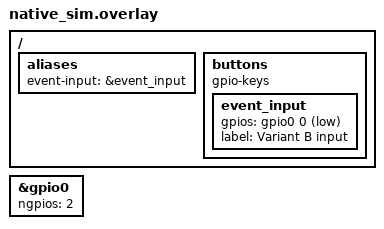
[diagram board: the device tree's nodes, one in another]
/ {
	aliases {
		event-input = &event_input;
	};

	buttons {
		compatible = "gpio-keys";

		event_input: event_input {
			gpios = <&gpio0 0 GPIO_ACTIVE_LOW>;
			label = "Variant B input";
		};
	};
};

&gpio0 {
	ngpios = <2>;
};
